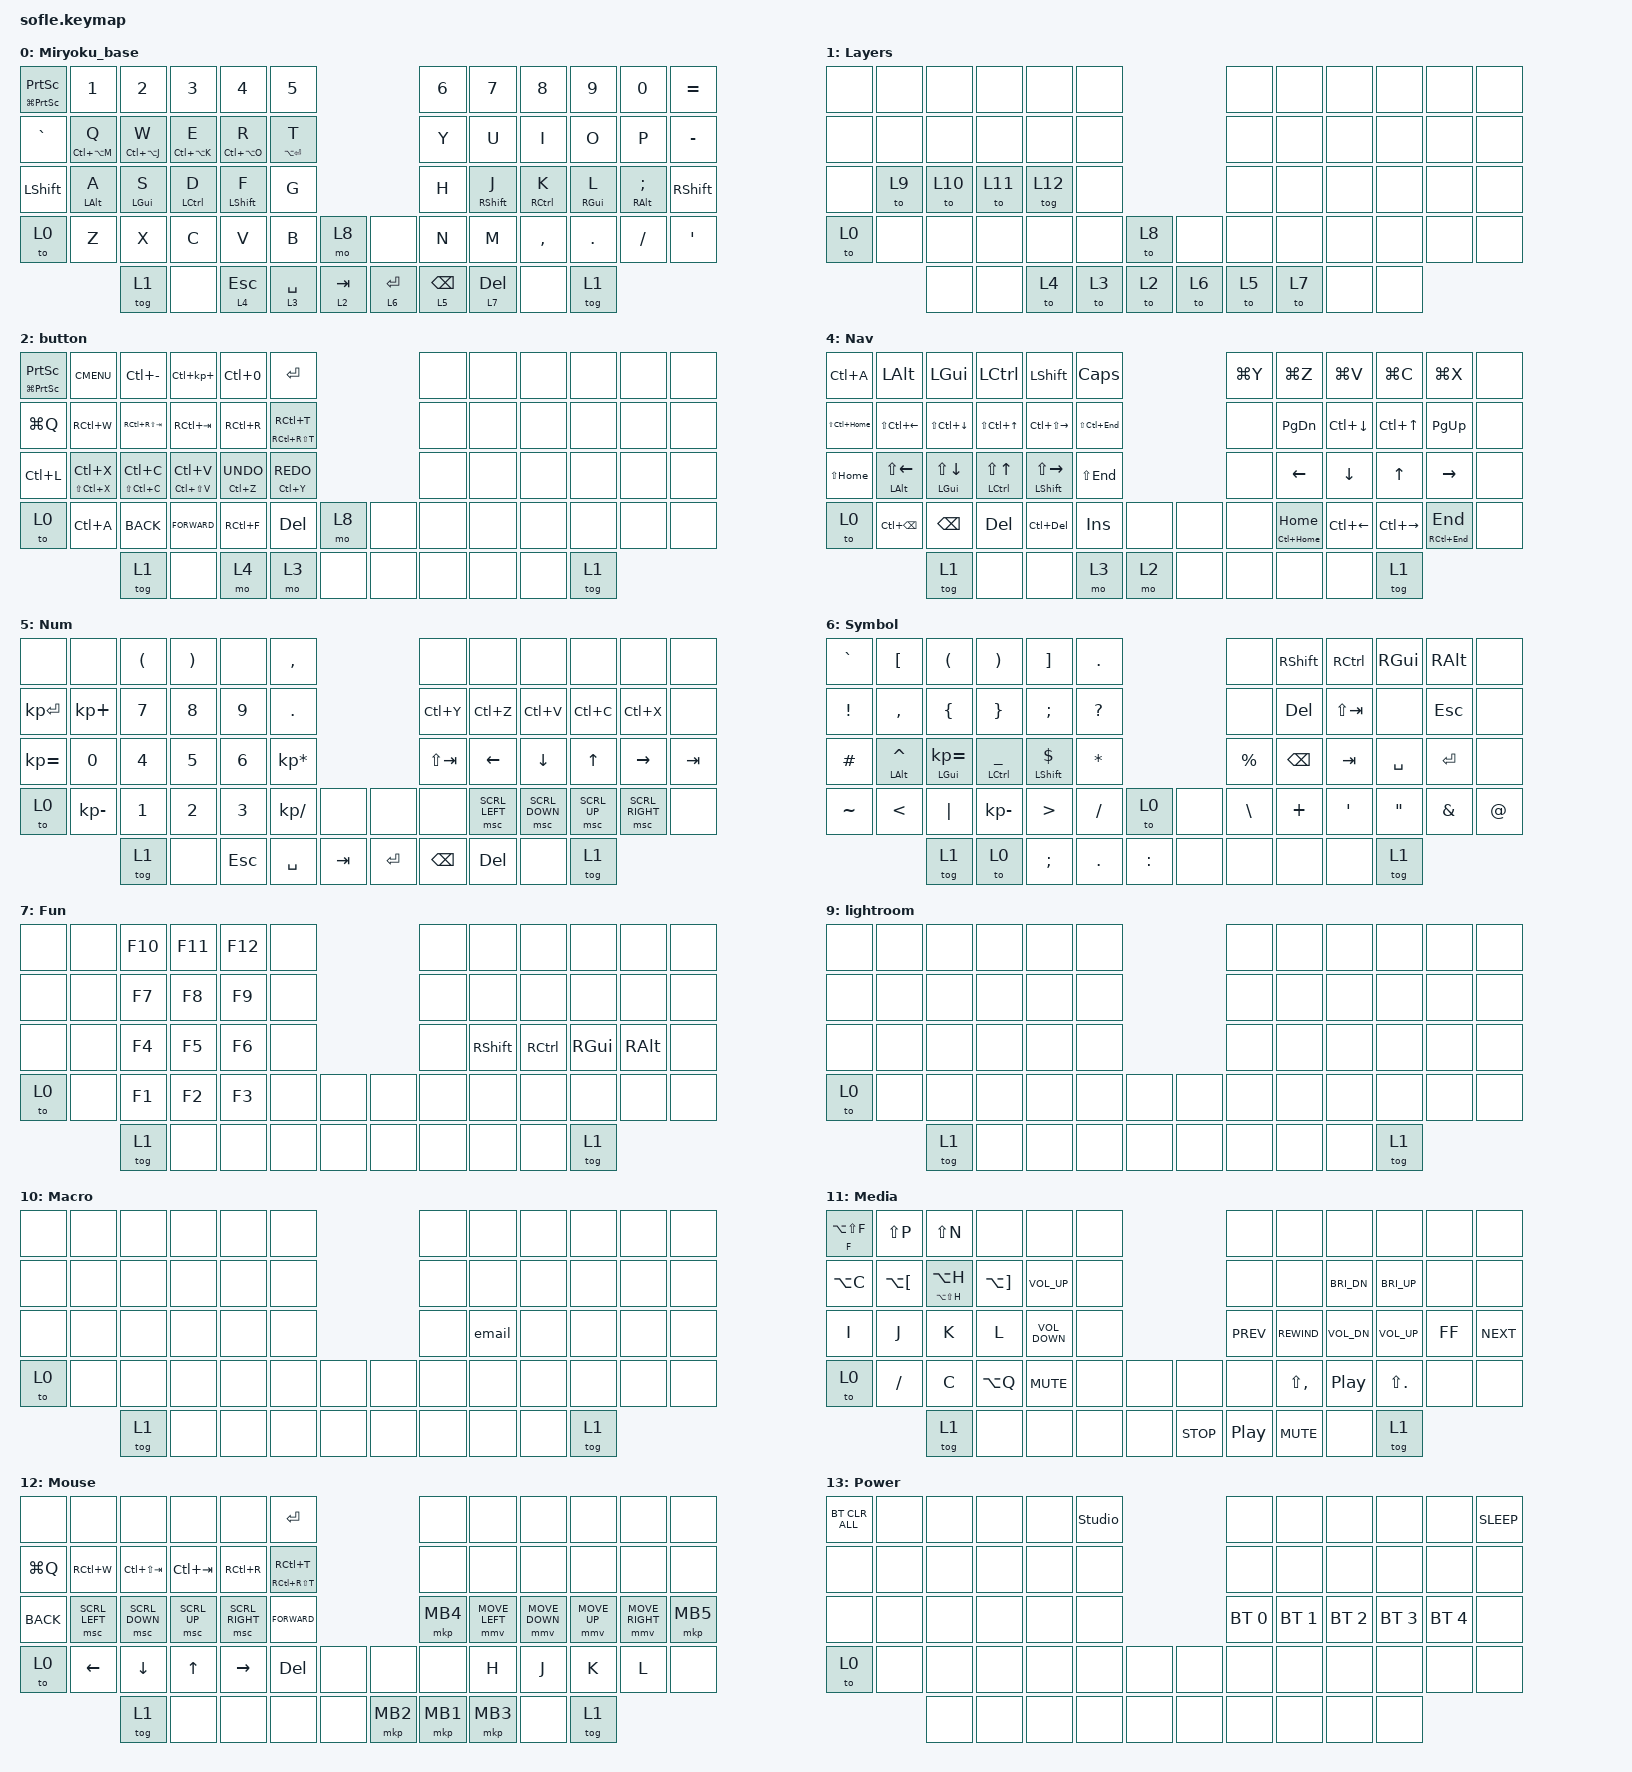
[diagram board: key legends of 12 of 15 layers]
/*
 * Copyright (c) 2020 The ZMK Contributors
 *
 * SPDX-License-Identifier: MIT
 */

#include <behaviors.dtsi>
#include <dt-bindings/zmk/bt.h>
#include <dt-bindings/zmk/keys.h>
#include <dt-bindings/zmk/pointing.h>

/* --- Raise default mouse/scroll top speed (device-side) ---
 * You can bump MOVE_VAL higher (e.g., 2600–3000) if you want even more speed.
 * SCRL_VAL controls the default for SCRL_* (keyboard wheel) behaviors.
 */

#define ZMK_POINTING_DEFAULT_MOVE_VAL 2000
#define ZMK_POINTING_DEFAULT_SCRL_VAL 5

/*
#define BASE 0
#define LOWER 1
#define RAISE 2
#define ADJUST 3
#define extra_layer 4
*/

&mt {
    quick-tap-ms = <175>;
    flavor = "balanced";
    require-prior-idle-ms = <150>;
    hold-trigger-on-release;
    tapping-term-ms = <280>;
    hold-trigger-key-positions = <6 7 8 9 10 11 18 19 20 21 22 23 30 31 32 33 34 35 44 45 46 47 48 49 55 56 57 58 59 43>;
};

&mmv {
    trigger-period-ms = <8>;
    time-to-max-speed-ms = <180>;
    acceleration-exponent = <2>;
};

&msc {
    time-to-max-speed-ms = <90>;
    acceleration-exponent = <1>;
    trigger-period-ms = <10>;
};

/ {
    // Activate ADJUST layer by pressing raise and lower

    conditional_layers {
        compatible = "zmk,conditional-layers";

        Media {
            if-layers = <4 3>;
            then-layer = <11>;
        };

        Mouse {
            if-layers = <3 2>;
            then-layer = <12>;
        };

        Power {
            if-layers = <4 2>;
            then-layer = <13>;
        };

        Lightroom {
            if-layers = <3 8>;
            then-layer = <9>;
        };

        Macro {
            if-layers = <2 8>;
            then-layer = <10>;
        };
    };

    combos {
        compatible = "zmk,combos";

        numtog {
            bindings = <&tog 5>;
            key-positions = <51 58>;
        };

        ms_scrl_down {
            bindings = <&msc SCRL_DOWN>;
            key-positions = <26 27>;
            timeout-ms = <25>;
        };

        msscrlup {
            bindings = <&msc SCRL_UP>;
            key-positions = <27 28>;
        };

        back {
            bindings = <&kp K_BACK>;
            key-positions = <38 39>;
        };

        forward {
            bindings = <&kp K_FORWARD>;
            key-positions = <39 40>;
        };

        reopenclosedtab {
            bindings = <&kp LC(LS(T))>;
            key-positions = <37 38 39>;
        };

        close {
            bindings = <&kp LG(Q)>;
            key-positions = <28 27 26 25>;
        };

        launcher {
            bindings = <&kp LG(SPACE)>;
            key-positions = <28 27 26>;
            timeout-ms = <20>;
            require-prior-idle-ms = <100>;
        };

        closetab {
            bindings = <&kp LC(W)>;
            key-positions = <25 27 26>;
        };

        windowresize {
            bindings = <&kp LG(N)>;
            key-positions = <16 13>;
        };

        focuscenter {
            bindings = <&kp LG(H)>;
            key-positions = <15 14>;
            timeout-ms = <20>;
            require-prior-idle-ms = <100>;
        };

        delete {
            bindings = <&kp DEL>;
            key-positions = <13 14>;
        };

        leftclickmouse {
            bindings = <&mkp MB1>;
            key-positions = <15 16>;
            require-prior-idle-ms = <100>;
            timeout-ms = <15>;
        };

        return {
            bindings = <&kp RETURN>;
            key-positions = <14 15 16>;
            timeout-ms = <40>;
        };

        deletehold {
            bindings = <&kp DELETE>;
            key-positions = <46 47>;
        };

        backspacehold {
            bindings = <&kp BACKSPACE>;
            key-positions = <45 46>;
        };

        fullsizewindow {
            bindings = <&kp LG(F)>;
            key-positions = <16 15 14 13>;
        };

        overview {
            bindings = <&kp LG(Y)>;
            key-positions = <17 12>;
        };

        heighpresets {
            bindings = <&kp LG(LS(N))>;
            key-positions = <4 1>;
        };

        reload {
            bindings = <&kp LC(R)>;
            key-positions = <40 37>;
        };

        zoomin {
            bindings = <&kp LC(KP_PLUS)>;
            key-positions = <28 25>;
        };

        zoomout {
            bindings = <&kp LC(KP_MINUS)>;
            key-positions = <29 24>;
        };

        chrome {
            bindings = <&kp LA(LC(K))>;
            key-positions = <29 28>;
        };
    };

    behaviors {
        caps: caps {
            compatible = "zmk,behavior-caps-word";
            label = "CAPS";
            #binding-cells = <0>;
            continue-list = <POUND MINUS BACKSPACE UNDERSCORE>;
        };
    };

    macros {
        email: email {
            compatible = "zmk,behavior-macro";
            #binding-cells = <0>;
            bindings = <&kp S &kp A &kp M &kp W &kp A &kp L &kp L &kp A &kp C &kp K &kp AT &kp G &kp M &kp A &kp I &kp L &kp DOT &kp C &kp O &kp M>;
            label = "EMAIL";
        };

        focusscrollleft: focusscrollleft {
            compatible = "zmk,behavior-macro";
            #binding-cells = <0>;
            bindings = <&kp LG(LEFT) &kp LG(H)>;
            label = "FOCUSSCROLLLEFT";
        };

        focusscrollright: focusscrollright {
            compatible = "zmk,behavior-macro";
            #binding-cells = <0>;
            bindings = <&kp LG(RIGHT) &kp LG(H)>;
            label = "FOCUSSCROLLRIGHT";
        };
    };

    keymap {
        compatible = "zmk,keymap";

        Miryoku_base {
            bindings = <
&mt LG(PRINTSCREEN) PRINTSCREEN  &kp N1           &kp N2           &kp N3           &kp N4            &kp N5                                       &kp N6           &kp N7             &kp N8       &kp N9           &kp N0              &kp EQUAL
&kp GRAVE                        &mt LC(LA(M)) Q  &mt LC(LA(J)) W  &mt LC(LA(K)) E  &mt LC(LA(O)) R   &mt LA(RETURN) T                             &kp Y            &kp U              &kp I        &kp O            &kp P               &kp MINUS
&kp LSHFT                        &mt LEFT_ALT A   &mt LEFT_GUI S   &mt LCTRL D      &mt LEFT_SHIFT F  &kp G                                        &kp H            &mt RIGHT_SHIFT J  &mt RCTRL K  &mt RIGHT_GUI L  &mt RIGHT_ALT SEMI  &kp RIGHT_SHIFT
&to 0                            &kp Z            &kp X            &kp C            &kp V             &kp B             &mo 8        &none         &kp N            &kp M              &kp COMMA    &kp DOT          &kp FSLH            &kp APOSTROPHE
                                                  &tog 1           &none            &lt 4 ESC         &lt 3 SPACE       &lt 2 TAB    &lt 6 RETURN  &lt 5 BACKSPACE  &lt 7 DELETE       &none        &tog 1
            >;
        };

        Layers {
            bindings = <
&none  &none  &none   &none   &none    &none                  &none  &none  &none  &none  &none  &none
&none  &none  &none   &none   &none    &none                  &none  &none  &none  &none  &none  &none
&none  &to 9  &to 10  &to 11  &tog 12  &none                  &none  &none  &none  &none  &none  &none
&to 0  &none  &none   &none   &none    &none  &to 8    &none  &none  &none  &none  &none  &none  &none
              &none   &none   &to 4    &to 3  &to 2    &to 6  &to 5  &to 7  &none  &none
            >;
        };

        button {
            bindings = <
&mt LG(PRINTSCREEN) PRINTSCREEN  &kp K_CMENU          &kp LC(MINUS)        &kp LC(KP_PLUS)      &kp LC(N0)        &kp RETURN                           &none  &none  &none  &none   &none  &none
&kp LG(Q)                        &kp RC(W)            &kp RC(RS(TAB))      &kp RC(TAB)          &kp RC(R)         &mt RC(RS(T)) RC(T)                  &none  &none  &none  &none   &none  &none
&kp LC(L)                        &mt LS(LC(X)) LC(X)  &mt LS(LC(C)) LC(C)  &mt LC(LS(V)) LC(V)  &mt LC(Z) K_UNDO  &mt LC(Y) K_REDO                     &none  &none  &none  &none   &none  &none
&to 0                            &kp LC(A)            &kp K_BACK           &kp K_FORWARD        &kp RC(F)         &kp DELETE           &mo 8    &none  &none  &none  &none  &none   &none  &none
                                                      &tog 1               &none                &mo 4             &mo 3                &none    &none  &none  &none  &none  &tog 1
            >;
        };

        TWM {
            bindings = <
&mt LG(P) LG(B)  &none                              &mt LG(LS(LC(DOWN))) LG(LS(DOWN))  &mt LG(LS(LC(UP))) LG(LS(UP_ARROW))  &none                              &mt LG(LS(F)) LG(F)                  &none          &none                                &none                              &none                                      &none                            &none
&kp LG(COMMA)    &mt LG(LC(HOME)) LC(LG(J))         &mt LG(LC(LS(DOWN))) LG(LC(K))     &mt LG(LS(LC(UP_ARROW))) LG(LC(I))   &kp LG(LC(L))                      &kp LG(PERIOD)                       &kp LG(Y)      &none                                &none                              &none                                      &none                            &none
&none            &mt LG(HOME) LG(LEFT)              &mt LG(LS(DOWN)) LG(DOWN)          &mt LG(LS(UP_ARROW)) LG(UP)          &mt LG(Q) LG(RIGHT_ARROW)          &mt LG(LS(H)) LG(H)                  &none          &mt LG(LC(PAGE_DOWN)) LG(PAGE_DOWN)  &mt LG(LS(LC(DOWN))) LG(LS(DOWN))  &mt LG(LS(LC(UP_ARROW))) LG(LS(UP_ARROW))  &mt LG(LC(PAGE_UP)) LG(PAGE_UP)  &none
&to 0            &mt LG(LC(NUMBER_1)) LG(NUMBER_1)  &mt LG(LC(NUMBER_2)) LG(NUMBER_2)  &mt LG(LC(NUMBER_3)) LG(NUMBER_3)    &mt LG(LC(NUMBER_4)) LG(NUMBER_4)  &mt LG(LS(N)) LG(N)  &mo 8    &none  &kp RG(RS(N))  &mt LG(LC(N5)) LG(N5)                &mt LG(LC(NUMBER_6)) LG(NUMBER_6)  &mt LG(LC(N7)) LG(N7)                      &mt LG(LC(N8)) LG(N8)            &none
                                                    &tog 1                             &none                                &mo 4                              &none                &mo 2    &none  &none          &none                                &none                              &tog 1
            >;
        };

        Nav {
            bindings = <
&kp LC(A)         &kp LEFT_ALT           &kp LEFT_GUI           &kp LCTRL               &kp LEFT_SHIFT            &kp CAPSLOCK                     &kp LG(Y)  &kp LG(Z)          &kp LG(V)     &kp LG(C)         &kp LG(X)        &none
&kp LS(LC(HOME))  &kp LS(LC(LEFT))       &kp LS(LC(DOWN))       &kp LS(LC(UP_ARROW))    &kp LC(LS(RIGHT))         &kp LS(LC(END))                  &none      &kp PAGE_DOWN      &kp LC(DOWN)  &kp LC(UP_ARROW)  &kp PG_UP        &none
&kp LS(HOME)      &mt LEFT_ALT LS(LEFT)  &mt LEFT_GUI LS(DOWN)  &mt LCTRL LS(UP_ARROW)  &mt LEFT_SHIFT LS(RIGHT)  &kp LS(END)                      &none      &kp LEFT           &kp DOWN      &kp UP            &kp RIGHT        &none
&to 0             &kp LC(BACKSPACE)      &kp BACKSPACE          &kp DEL                 &kp LC(DELETE)            &kp INSERT       &none    &none  &none      &mt LC(HOME) HOME  &kp LC(LEFT)  &kp LC(RIGHT)     &mt RC(END) END  &none
                                         &tog 1                 &none                   &none                     &mo 3            &mo 2    &none  &none      &none              &none         &tog 1
            >;
        };

        Num {
            bindings = <
&none         &none            &kp LEFT_PARENTHESIS  &kp RIGHT_PARENTHESIS  &none    &kp COMMA                            &none        &none           &none           &none         &none            &none
&kp KP_ENTER  &kp KP_PLUS      &kp N7                &kp N8                 &kp N9   &kp DOT                              &kp LC(Y)    &kp LC(Z)       &kp LC(V)       &kp LC(C)     &kp LC(X)        &none
&kp KP_EQUAL  &kp N0           &kp N4                &kp N5                 &kp N6   &kp KP_MULTIPLY                      &kp LS(TAB)  &kp LEFT        &kp DOWN        &kp UP        &kp RIGHT        &kp TAB
&to 0         &kp KP_SUBTRACT  &kp N1                &kp N2                 &kp N3   &kp KP_DIVIDE    &none      &none    &none        &msc SCRL_LEFT  &msc SCRL_DOWN  &msc SCRL_UP  &msc SCRL_RIGHT  &none
                               &tog 1                &none                  &kp ESC  &kp SPACE        &kp TAB    &kp RET  &kp BSPC     &kp DEL         &none           &tog 1
            >;
        };

        Symbol {
            bindings = <
&kp GRAVE  &kp LEFT_BRACKET    &kp LEFT_PARENTHESIS   &kp RIGHT_PARENTHESIS  &kp RIGHT_BRACKET      &kp PERIOD                        &none          &kp RIGHT_SHIFT  &kp RCTRL    &kp RIGHT_GUI      &kp RIGHT_ALT  &none
&kp EXCL   &kp COMMA           &kp LEFT_BRACE         &kp RIGHT_BRACE        &kp SEMICOLON          &kp QUESTION                      &none          &kp DEL          &kp LS(TAB)  &none              &kp ESCAPE     &none
&kp POUND  &mt LEFT_ALT CARET  &mt LEFT_GUI KP_EQUAL  &mt LCTRL UNDER        &mt LEFT_SHIFT DOLLAR  &kp ASTERISK                      &kp PERCENT    &kp BSPC         &kp TAB      &kp SPACE          &kp RET        &none
&kp TILDE  &kp LESS_THAN       &kp PIPE               &kp KP_MINUS           &kp GREATER_THAN       &kp FSLH      &to 0        &none  &kp BACKSLASH  &kp PLUS         &kp SQT      &kp DOUBLE_QUOTES  &kp AMPERSAND  &kp AT
                               &tog 1                 &to 0                  &kp SEMICOLON          &kp PERIOD    &kp COLON    &none  &none          &none            &none        &tog 1
            >;
        };

        Fun {
            bindings = <
&none  &none  &kp F10  &kp F11  &kp F12  &none                  &none  &none            &none      &none          &none          &none
&none  &none  &kp F7   &kp F8   &kp F9   &none                  &none  &none            &none      &none          &none          &none
&none  &none  &kp F4   &kp F5   &kp F6   &none                  &none  &kp RIGHT_SHIFT  &kp RCTRL  &kp RIGHT_GUI  &kp RIGHT_ALT  &none
&to 0  &none  &kp F1   &kp F2   &kp F3   &none  &none    &none  &none  &none            &none      &none          &none          &none
              &tog 1   &none    &none    &none  &none    &none  &none  &none            &none      &tog 1
            >;
        };

        Launcher {
            bindings = <
&none          &none          &none          &none              &none          &none                          &none          &none  &none  &none   &kp LC(LA(P))  &none
&none          &none          &kp LA(L)      &kp LC(LA(LS(K)))  &none          &kp LC(LA(O))                  &none          &none  &none  &none   &none          &none
&kp LC(LA(I))  &kp LC(LA(J))  &kp LC(LA(U))  &kp LC(LA(K))      &kp LG(SPACE)  &kp LC(LA(M))                  &kp LC(LA(Y))  &none  &none  &none   &none          &none
&to 0          &kp LC(LA(H))  &none          &none              &none          &none          &none    &none  &none          &none  &none  &none   &none          &none
                              &tog 1         &none              &none          &mo 3          &mo 2    &none  &none          &none  &none  &tog 1
            >;
        };

        lightroom {
            bindings = <
&none  &none  &none   &none  &none  &none                  &none  &none  &none  &none   &none  &none
&none  &none  &none   &none  &none  &none                  &none  &none  &none  &none   &none  &none
&none  &none  &none   &none  &none  &none                  &none  &none  &none  &none   &none  &none
&to 0  &none  &none   &none  &none  &none  &none    &none  &none  &none  &none  &none   &none  &none
              &tog 1  &none  &none  &none  &none    &none  &none  &none  &none  &tog 1
            >;
        };

        Macro {
            bindings = <
&none  &none  &none   &none  &none  &none                  &none  &none   &none  &none   &none  &none
&none  &none  &none   &none  &none  &none                  &none  &none   &none  &none   &none  &none
&none  &none  &none   &none  &none  &none                  &none  &email  &none  &none   &none  &none
&to 0  &none  &none   &none  &none  &none  &none    &none  &none  &none   &none  &none   &none  &none
              &tog 1  &none  &none  &none  &none    &none  &none  &none   &none  &tog 1
            >;
        };

        Media {
            bindings = <
&mt F LA(LS(F))  &kp LS(P)             &kp LS(N)            &none                  &none              &none                       &none             &none          &none             &none           &none     &none
&kp LA(C)        &kp LA(LEFT_BRACKET)  &mt LA(LS(H)) LA(H)  &kp LA(RIGHT_BRACKET)  &kp C_VOLUME_UP    &none                       &none             &none          &kp C_BRI_DN      &kp C_BRI_UP    &none     &none
&kp I            &kp J                 &kp K                &kp L                  &kp C_VOLUME_DOWN  &none                       &kp C_PREV        &kp C_REWIND   &kp C_VOL_DN      &kp C_VOL_UP    &kp C_FF  &kp C_NEXT
&to 0            &kp SLASH             &kp C                &kp LA(Q)              &kp C_MUTE         &none  &none    &none       &none             &kp LS(COMMA)  &kp C_PLAY_PAUSE  &kp LS(PERIOD)  &none     &none
                                       &tog 1               &none                  &none              &none  &none    &kp C_STOP  &kp C_PLAY_PAUSE  &kp C_MUTE     &none             &tog 1
            >;
        };

        Mouse {
            bindings = <
&none       &none           &none            &none         &none            &kp RETURN                              &none     &none           &none           &none         &none            &none
&kp LG(Q)   &kp RC(W)       &kp LC(LS(TAB))  &kp LC(TAB)   &kp RC(R)        &mt RC(RS(T)) RC(T)                     &none     &none           &none           &none         &none            &none
&kp K_BACK  &msc SCRL_LEFT  &msc SCRL_DOWN   &msc SCRL_UP  &msc SCRL_RIGHT  &kp K_FORWARD                           &mkp MB4  &mmv MOVE_LEFT  &mmv MOVE_DOWN  &mmv MOVE_UP  &mmv MOVE_RIGHT  &mkp MB5
&to 0       &kp LEFT        &kp DOWN         &kp UP        &kp RIGHT        &kp DELETE           &none    &none     &none     &kp H           &kp J           &kp K         &kp L            &none
                            &tog 1           &none         &none            &none                &none    &mkp MB2  &mkp MB1  &mkp MB3        &none           &tog 1
            >;
        };

        Power {
            bindings = <
&bt BT_CLR_ALL  &none  &none  &none  &none  &studio_unlock                  &none         &none         &none         &none         &none         &kp C_SLEEP
&none           &none  &none  &none  &none  &none                           &none         &none         &none         &none         &none         &none
&none           &none  &none  &none  &none  &none                           &bt BT_SEL 0  &bt BT_SEL 1  &bt BT_SEL 2  &bt BT_SEL 3  &bt BT_SEL 4  &none
&to 0           &none  &none  &none  &none  &none           &none    &none  &none         &none         &none         &none         &none         &none
                       &none  &none  &none  &none           &none    &none  &none         &none         &none         &none
            >;
        };

        symbol_og {
            bindings = <
&kp AT     &kp GRAVE           &kp LEFT_PARENTHESIS   &kp RIGHT_PARENTHESIS  &kp SEMICOLON          &kp COMMA                         &none          &kp RIGHT_SHIFT  &kp RCTRL         &kp RIGHT_GUI      &kp RIGHT_ALT  &none
&kp EXCL   &kp LEFT_BRACE      &kp APOSTROPHE         &kp DOUBLE_QUOTES      &kp RIGHT_BRACE        &kp QUESTION                      &none          &kp DEL          &kp LS(TAB)       &none              &kp ESCAPE     &none
&kp POUND  &mt LEFT_ALT CARET  &mt LEFT_GUI KP_EQUAL  &mt LCTRL UNDER        &mt LEFT_SHIFT DOLLAR  &kp ASTERISK                      &kp PERCENT    &kp BSPC         &kp TAB           &kp SPACE          &kp RET        &none
&kp TILDE  &kp LESS_THAN       &kp PIPE               &kp KP_MINUS           &kp GREATER_THAN       &kp FSLH      &to 0        &none  &kp BACKSLASH  &kp PLUS         &kp LEFT_BRACKET  &kp RIGHT_BRACKET  &kp AMPERSAND  &kp AT
                               &tog 1                 &to 0                  &kp SEMICOLON          &kp PERIOD    &kp COLON    &none  &none          &none            &none             &tog 1
            >;
        };
    };
};
